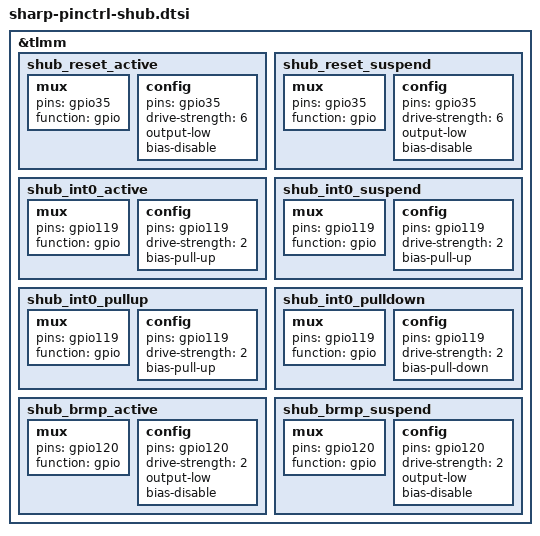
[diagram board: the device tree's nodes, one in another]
/* Copyright (c) 2013-2014, The Linux Foundation. All rights reserved.
 *
 * This program is free software; you can redistribute it and/or modify
 * it under the terms of the GNU General Public License version 2 and
 * only version 2 as published by the Free Software Foundation.
 *
 * This program is distributed in the hope that it will be useful,
 * but WITHOUT ANY WARRANTY; without even the implied warranty of
 * MERCHANTABILITY or FITNESS FOR A PARTICULAR PURPOSE.  See the
 * GNU General Public License for more details.
 */

&tlmm {
	/*****************************************/
	/*  pinctrl customize setting            */
	/*  SensorHub                            */
	/*****************************************/
	shub_reset_active: shub_reset_active {
		mux {
			pins = "gpio35";
			function = "gpio";
		};
		config {
			pins = "gpio35";
			drive-strength = <6>;
			output-low;
			bias-disable;
		};
	};
	shub_reset_suspend: shub_reset_suspend {
		mux {
			pins = "gpio35";
			function = "gpio";
		};
		config {
			pins = "gpio35";
			drive-strength = <6>;
			output-low;
			bias-disable;
		};
	};

	shub_int0_active: shub_int0_active {
		mux {
			pins = "gpio119";
			function = "gpio";
		};
		config {
			pins = "gpio119";
			drive-strength = <2>;
			bias-pull-up;
		};
	};
	shub_int0_suspend: shub_int0_suspend {
		mux {
			pins = "gpio119";
			function = "gpio";
		};
		config {
			pins = "gpio119";
			drive-strength = <2>;
			bias-pull-up;
		};
	};
	shub_int0_pullup: shub_int0_pullup {
		mux {
			pins = "gpio119";
			function = "gpio";
		};
		config {
			pins = "gpio119";
			drive-strength = <2>;
			bias-pull-up;
		};
	};
	shub_int0_pulldown: shub_int0_pulldown {
		mux {
			pins = "gpio119";
			function = "gpio";
		};
		config {
			pins = "gpio119";
			drive-strength = <2>;
			bias-pull-down;
		};
	};

	shub_brmp_active: shub_brmp_active {
		mux {
			pins = "gpio120";
			function = "gpio";
		};
		config {
			pins = "gpio120";
			drive-strength = <2>;
			output-low;
			bias-disable;
		};
	};
	shub_brmp_suspend: shub_brmp_suspend {
		mux {
			pins = "gpio120";
			function = "gpio";
		};
		config {
			pins = "gpio120";
			drive-strength = <2>;
			output-low;
			bias-disable;
		};
	};
};

